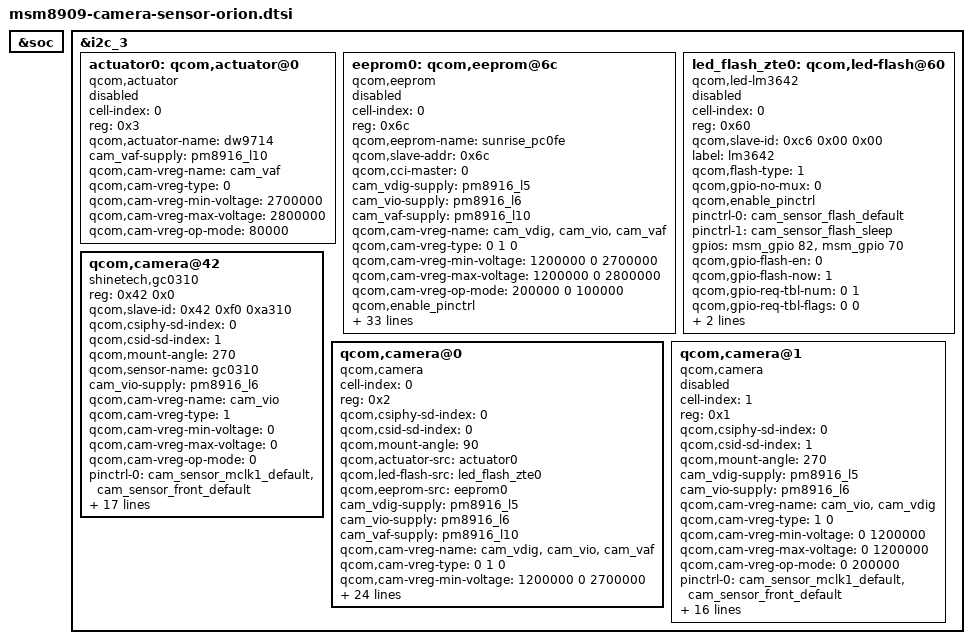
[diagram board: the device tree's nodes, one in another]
/*
 * Copyright (c) 2014-2015, The Linux Foundation. All rights reserved.
 *
 * This program is free software; you can redistribute it and/or modify
 * it under the terms of the GNU General Public License version 2 and
 * only version 2 as published by the Free Software Foundation.
 *
 * This program is distributed in the hope that it will be useful,
 * but WITHOUT ANY WARRANTY; without even the implied warranty of
 * MERCHANTABILITY or FITNESS FOR A PARTICULAR PURPOSE.  See the
 * GNU General Public License for more details.
 */

&soc {
};

&i2c_3 {

	actuator0: qcom,actuator@0 {
		cell-index = <0>;
		reg = <0x3>;
		//qcom,slave-addr = <0x18>;
		compatible = "qcom,actuator";
		qcom,actuator-name = "dw9714";
		/*qcom,cci-master = <0>;*/
		cam_vaf-supply = <&pm8916_l10>;
		qcom,cam-vreg-name = "cam_vaf";
		qcom,cam-vreg-type = <0>;
		qcom,cam-vreg-min-voltage = <2700000>;
		qcom,cam-vreg-max-voltage = <2800000>;
		qcom,cam-vreg-op-mode = <80000>;
		status = "disabled";
	};

	eeprom0: qcom,eeprom@6c{
		cell-index = <0>;
		reg = <0x6c>;
		qcom,eeprom-name = "sunrise_pc0fe";
		compatible = "qcom,eeprom";
		qcom,slave-addr = <0x6c>;
		qcom,cci-master = <0>;	
		
		cam_vdig-supply = <&pm8916_l5>;
		cam_vio-supply = <&pm8916_l6>;
		cam_vaf-supply = <&pm8916_l10>;
		qcom,cam-vreg-name = "cam_vdig", "cam_vio","cam_vaf";
		qcom,cam-vreg-type = <0 1 0>;
		qcom,cam-vreg-min-voltage = <1200000 0 2700000>;
		qcom,cam-vreg-max-voltage = <1200000 0 2800000>;
		qcom,cam-vreg-op-mode = <200000 0 100000>;
		qcom,enable_pinctrl;
		pinctrl-names = "cam_default", "cam_suspend";
		pinctrl-0 = <&cam_sensor_mclk0_default
					&cam_sensor_rear_default>;
		pinctrl-1 = <&cam_sensor_mclk0_sleep &cam_sensor_rear_sleep>;
		gpios = <&msm_gpio 26 0>,
			<&msm_gpio 35 0>,
			<&msm_gpio 34 0>,
			<&msm_gpio 17 0>,
			<&msm_gpio 16 0>,
			<&msm_gpio 99 0>;
		qcom,gpio-reset = <1>;
		qcom,gpio-standby = <2>;
		qcom,gpio-vio = <3>;
		qcom,gpio-vdig = <4>;
		qcom,gpio-vana = <5>;
		qcom,gpio-req-tbl-num = <0 1 2 3 4 5>;
		qcom,gpio-req-tbl-flags = <1 0 0 0 0 0>;
		qcom,gpio-req-tbl-label = "CAMIF_MCLK",
			"CAM_RESET1",
			"CAM_STANDBY",
			"CAM_VIO",
			"CAM_VDIG",
			"CAM_VANA";
		qcom,cam-power-seq-type = "sensor_gpio",
								     "sensor_gpio",
								     "sensor_gpio",
								     "sensor_gpio",
								     "sensor_gpio",
								     "sensor_gpio",
								     "sensor_clk",								     
								     "sensor_i2c_mux";
		qcom,cam-power-seq-val = "sensor_gpio_vio",
							     "sensor_gpio_vana",
							     "sensor_gpio_vdig",
							     "sensor_gpio_standby",
		               "sensor_gpio_reset",
							     "sensor_gpio_reset", 
							     "sensor_cam_mclk",    
							     "none";		 
		qcom,cam-power-seq-cfg-val = < 1 1 1 1 0 1 23880000  0>;
		qcom,cam-power-seq-delay =   < 1 1 1 5 5 10 10 0>;
		zte,num-blocks = <3>;
		zte,mem0    = <16	 0x7010  2 0x0 1 0>;	//id 
		zte,mem1    = <10	 0x7020  2 0x0 1 0>;  //wb
		zte,mem2    = <10	 0x702a  2 0x0 1 0>;  //af(qtech)
		clocks = <&clock_gcc clk_mclk0_clk_src>,
				<&clock_gcc clk_gcc_camss_mclk0_clk>;
		clock-names = "cam_src_clk", "cam_clk";
		status = "disabled";
	};
	
    /* add zte sensor dtsi for led-flash*/
	led_flash_zte0: qcom,led-flash@60 {
		cell-index = <0>;
		reg = <0x60>;
		qcom,slave-id = <0xc6 0x00 0x00>;
		compatible = "qcom,led-lm3642";
		label = "lm3642";
		qcom,flash-type = <1>;
		qcom,gpio-no-mux = <0>;
		qcom,enable_pinctrl;
		pinctrl-names = "cam_flash_default", "cam_flash_suspend";
		pinctrl-0 = <&cam_sensor_flash_default>;
		pinctrl-1 = <&cam_sensor_flash_sleep>;
		gpios = <&msm_gpio 82 0>,
			<&msm_gpio 70 0>;           /*32*/
		qcom,gpio-flash-en = <0>;
		qcom,gpio-flash-now = <1>;
		qcom,gpio-req-tbl-num = <0 1>;
		qcom,gpio-req-tbl-flags = <0 0>;
		qcom,gpio-req-tbl-label = "FLASH_EN",
			"FLASH_NOW";
		qcom,cci-master = <0>;
		status = "disabled";
	};


/*add by zte_cam_wxl_20150731 for gc0310 yuv sensor*/
	qcom,camera@42 {
		compatible = "shinetech,gc0310";
		reg = <0x42 0x0>;
		qcom,slave-id = <0x42 0xf0 0xa310>;
		qcom,csiphy-sd-index = <0>;
		qcom,csid-sd-index = <1>;
		qcom,mount-angle = <270>;
		qcom,sensor-name = "gc0310";
		cam_vio-supply = <&pm8916_l6>;
		qcom,cam-vreg-name = "cam_vio";
		qcom,cam-vreg-type = <1>;
		qcom,cam-vreg-min-voltage = <0>;
		qcom,cam-vreg-max-voltage = <0>;
		qcom,cam-vreg-op-mode = <0>;
		pinctrl-names = "cam_default", "cam_suspend";
		pinctrl-0 = <&cam_sensor_mclk1_default
				&cam_sensor_front_default>;
		pinctrl-1 = <&cam_sensor_mclk1_sleep &cam_sensor_front_sleep>;
		gpios = <&msm_gpio 27 0>,
			<&msm_gpio 35 0>,          /*28*/
			//<&msm_gpio 33 0>,
			<&msm_gpio 17 0>,
			<&msm_gpio 99 0>;
		qcom,gpio-reset = <1>;
		qcom,gpio-standby = <2>;
		qcom,gpio-vio = <3>;
		qcom,gpio-vana = <4>;
		qcom,gpio-req-tbl-num = <0 1 2 3 4>;
		qcom,gpio-req-tbl-flags = <1 0 0 0 0>;
		qcom,gpio-req-tbl-label = "CAMIF_MCLK",
			"CAM_RESET",
			"CAM_STANDBY",
			"CAM_VIO",
			"CAM_VANA";	
		qcom,csi-lane-assign = <0x0004>;
		//qcom,csi-lane-mask = <0x18>;
		qcom,sensor-position = <1>;
		qcom,sensor-mode = <0>;
		/*qcom,cci-master = <0>;*/
		clocks = <&clock_gcc clk_mclk1_clk_src>,
				<&clock_gcc clk_gcc_camss_mclk1_clk>;
		clock-names = "cam_src_clk", "cam_clk";
		status = "ok";
	};

	qcom,camera@0 {
		cell-index = <0>;
		compatible = "qcom,camera";
		reg = <0x2>;
		qcom,csiphy-sd-index = <0>;
		qcom,csid-sd-index = <0>;
		qcom,mount-angle = <90>;
		qcom,actuator-src = <&actuator0>;
		qcom,led-flash-src = <&led_flash_zte0>;
		qcom,eeprom-src = <&eeprom0>;
		cam_vdig-supply = <&pm8916_l5>;
		cam_vio-supply = <&pm8916_l6>;
		cam_vaf-supply = <&pm8916_l10>;
		qcom,cam-vreg-name = "cam_vdig", "cam_vio", "cam_vaf";
		qcom,cam-vreg-type = <0 1 0>;
		qcom,cam-vreg-min-voltage = <1200000 0 2700000>;
		qcom,cam-vreg-max-voltage = <1200000 0 2800000>;
		qcom,cam-vreg-op-mode = <200000 0 100000>;
		pinctrl-names = "cam_default", "cam_suspend";
		pinctrl-0 = <&cam_sensor_mclk0_default
				&cam_sensor_rear_default>;
		pinctrl-1 = <&cam_sensor_mclk0_sleep
				&cam_sensor_rear_sleep>;
		gpios = <&msm_gpio 26 0>,
			<&msm_gpio 35 0>,
			<&msm_gpio 34 0>,
			<&msm_gpio 17 0>,
			<&msm_gpio 16 0>,
			<&msm_gpio 99 0>,
			<&msm_gpio 72 0>;      /*98*/          
		qcom,gpio-reset = <1>;
		qcom,gpio-standby = <2>;
		qcom,gpio-vio = <3>;
		qcom,gpio-vdig = <4>;
		qcom,gpio-vana = <5>;
		qcom,gpio-vaf = <6>;
		qcom,gpio-req-tbl-num = <0 1 2 3 4 5 6>;
		qcom,gpio-req-tbl-flags = <1 0 0 0 0 0 0>;
		qcom,gpio-req-tbl-label = "CAMIF_MCLK",
			"CAM_RESET1",
			"CAM_STANDBY",
			"CAM_VIO",
			"CAM_VDIG",
			"CAM_VANA",
			"CAM_VAF";
		qcom,sensor-position = <0>;
		qcom,sensor-mode = <0>;
		/*qcom,cci-master = <0>;*/
		status = "ok";
		clocks = <&clock_gcc clk_mclk0_clk_src>,
				<&clock_gcc clk_gcc_camss_mclk0_clk>;
		clock-names = "cam_src_clk", "cam_clk";
	};

	qcom,camera@1 {
		cell-index = <1>;
		compatible = "qcom,camera";
		reg = <0x1>;
		qcom,csiphy-sd-index = <0>;
		qcom,csid-sd-index = <1>;
		qcom,mount-angle = <270>;
		cam_vdig-supply = <&pm8916_l5>;
		cam_vio-supply = <&pm8916_l6>;
		qcom,cam-vreg-name = "cam_vio", "cam_vdig";
		qcom,cam-vreg-type = <1 0>;
		qcom,cam-vreg-min-voltage = <0 1200000>;
		qcom,cam-vreg-max-voltage = <0 1200000>;
		qcom,cam-vreg-op-mode = <0 200000>;
		pinctrl-names = "cam_default", "cam_suspend";
		pinctrl-0 = <&cam_sensor_mclk1_default
				&cam_sensor_front_default>;		
		pinctrl-1 = <&cam_sensor_mclk1_sleep
				&cam_sensor_front_sleep>;
		gpios = <&msm_gpio 27 0>,
			<&msm_gpio 35 0>,      /*28*/         
			//<&msm_gpio 33 0>,
			<&msm_gpio 17 0>,
			<&msm_gpio 95 0>,
			<&msm_gpio 99 0>;
		qcom,gpio-reset = <1>;
		qcom,gpio-standby = <2>;
		qcom,gpio-vio = <3>;
		qcom,gpio-vdig = <4>;
		qcom,gpio-vana = <5>;
		qcom,gpio-req-tbl-num = <0 1 2 3 4 5>;
		qcom,gpio-req-tbl-flags = <1 0 0 0 0 0>;
		qcom,gpio-req-tbl-label = "CAMIF_MCLK",
			"CAM_RESET",
			"CAM_STANDBY",
			"CAM_VIO",
			"CAM_VDIG",
			"CAM_VANA";			
		/*qcom,cci-master = <0>;*/
		status = "disabled";
		clocks = <&clock_gcc clk_mclk1_clk_src>,
				<&clock_gcc clk_gcc_camss_mclk1_clk>;
		clock-names = "cam_src_clk", "cam_clk";
	};
};
